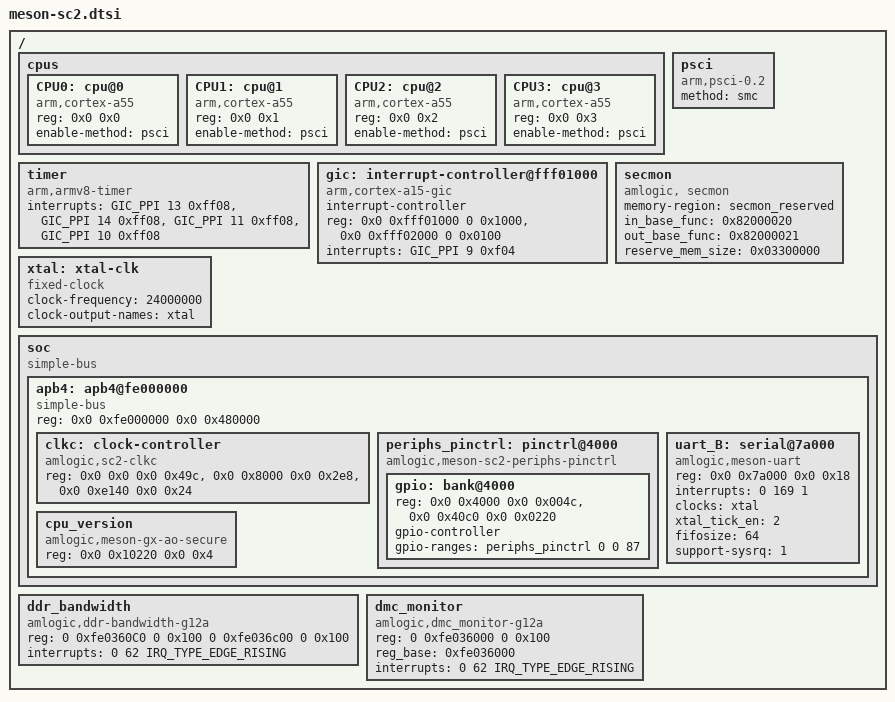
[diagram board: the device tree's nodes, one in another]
// SPDX-License-Identifier: (GPL-2.0+ OR MIT)
/*
 * Copyright (c) 2019 Amlogic, Inc. All rights reserved.
 */

#include <dt-bindings/clock/axg-audio-clkc.h>
#include <dt-bindings/clock/g12a-clkc.h>
#include <dt-bindings/clock/g12a-aoclkc.h>
#include <dt-bindings/interrupt-controller/irq.h>
#include <dt-bindings/interrupt-controller/arm-gic.h>
#include <dt-bindings/power/meson-sm1-power.h>
#include <dt-bindings/clock/amlogic,sm1-audio-clk.h>
#include <dt-bindings/gpio/gpio.h>
#include <dt-bindings/gpio/meson-sc2-gpio.h>

/ {
	cpus:cpus {
		#address-cells = <2>;
		#size-cells = <0>;

		CPU0:cpu@0 {
			device_type = "cpu";
			compatible = "arm,cortex-a55","arm,armv8";
			reg = <0x0 0x0>;
			enable-method = "psci";
		};

		CPU1:cpu@1 {
			device_type = "cpu";
			compatible = "arm,cortex-a55","arm,armv8";
			reg = <0x0 0x1>;
			enable-method = "psci";
		};

		CPU2:cpu@2 {
			device_type = "cpu";
			compatible = "arm,cortex-a55","arm,armv8";
			reg = <0x0 0x2>;
			enable-method = "psci";
		};

		CPU3:cpu@3 {
			device_type = "cpu";
			compatible = "arm,cortex-a55","arm,armv8";
			reg = <0x0 0x3>;
			enable-method = "psci";
		};
	};

	timer {
		compatible = "arm,armv8-timer";
		interrupts = <GIC_PPI 13 0xff08>,
				<GIC_PPI 14 0xff08>,
				<GIC_PPI 11 0xff08>,
				<GIC_PPI 10 0xff08>;
	};

	gic: interrupt-controller@fff01000 {
		compatible = "arm,cortex-a15-gic", "arm,cortex-a9-gic";
		#interrupt-cells = <3>;
		#address-cells = <0>;
		interrupt-controller;
		reg = <0x0 0xfff01000 0 0x1000>,
		      <0x0 0xfff02000 0 0x0100>;
		interrupts = <GIC_PPI 9 0xf04>;
	};

	psci {
		compatible = "arm,psci-0.2";
		method = "smc";
	};

	secmon {
		compatible = "amlogic, secmon";
		memory-region = <&secmon_reserved>;
		in_base_func = <0x82000020>;
		out_base_func = <0x82000021>;
		reserve_mem_size = <0x03300000>;
	};

	xtal: xtal-clk {
		compatible = "fixed-clock";
		clock-frequency = <24000000>;
		clock-output-names = "xtal";
		#clock-cells = <0>;
	};

	soc {
		compatible = "simple-bus";
		#address-cells = <2>;
		#size-cells = <2>;
		ranges;

		apb4: apb4@fe000000 {
			compatible = "simple-bus";
			reg = <0x0 0xfe000000 0x0 0x480000>;
			#address-cells = <2>;
			#size-cells = <2>;
			ranges = <0x0 0x0 0x0 0xfe000000 0x0 0x480000>;

			clkc: clock-controller {
				compatible = "amlogic,sc2-clkc";
				#clock-cells = <1>;
				reg = <0x0 0x0 0x0 0x49c>,
				      <0x0 0x8000 0x0 0x2e8>,
				      <0x0 0xe140 0x0 0x24>;
				status = "okay";
			};

			periphs_pinctrl: pinctrl@4000 {
				compatible = "amlogic,meson-sc2-periphs-pinctrl";
				#address-cells = <2>;
				#size-cells = <2>;
				ranges;

				gpio: bank@4000 {
					reg = <0x0 0x4000 0x0 0x004c>,
					      <0x0 0x40c0 0x0 0x0220>;
					reg-names = "mux", "gpio";
					gpio-controller;
					#gpio-cells = <2>;
					gpio-ranges = <&periphs_pinctrl 0 0 87>;
				};

			};

			uart_B: serial@7a000 {
				compatible = "amlogic,meson-uart";
				reg = <0x0 0x7a000 0x0 0x18>;
				interrupts = <0 169 1>;
				status = "okay";
				clocks = <&xtal>;
				clock-names = "clk_uart";
				xtal_tick_en = <2>;
				fifosize = < 64 >;
				pinctrl-names = "default";
				/*pinctrl-0 = <&ao_uart_pins>;*/
				support-sysrq = <1>;  /* 0 not support*/
			};
			cpu_version {
				compatible = "amlogic,meson-gx-ao-secure", "syscon";
				reg=<0x0 0x10220 0x0 0x4>;
			};
		};
	};

	ddr_bandwidth {
		compatible = "amlogic,ddr-bandwidth-g12a";
		status = "okay";
		reg = <0 0xfe0360C0 0 0x100
		       0 0xfe036c00 0 0x100>;
		interrupts = <0 62 IRQ_TYPE_EDGE_RISING>;
		interrupt-names = "ddr_bandwidth";
	};
	dmc_monitor {
		compatible = "amlogic,dmc_monitor-g12a";
		status = "okay";
		reg = <0 0xfe036000 0 0x100>;
		reg_base = <0xfe036000>;
		interrupts = <0 62 IRQ_TYPE_EDGE_RISING>;
	};

};
